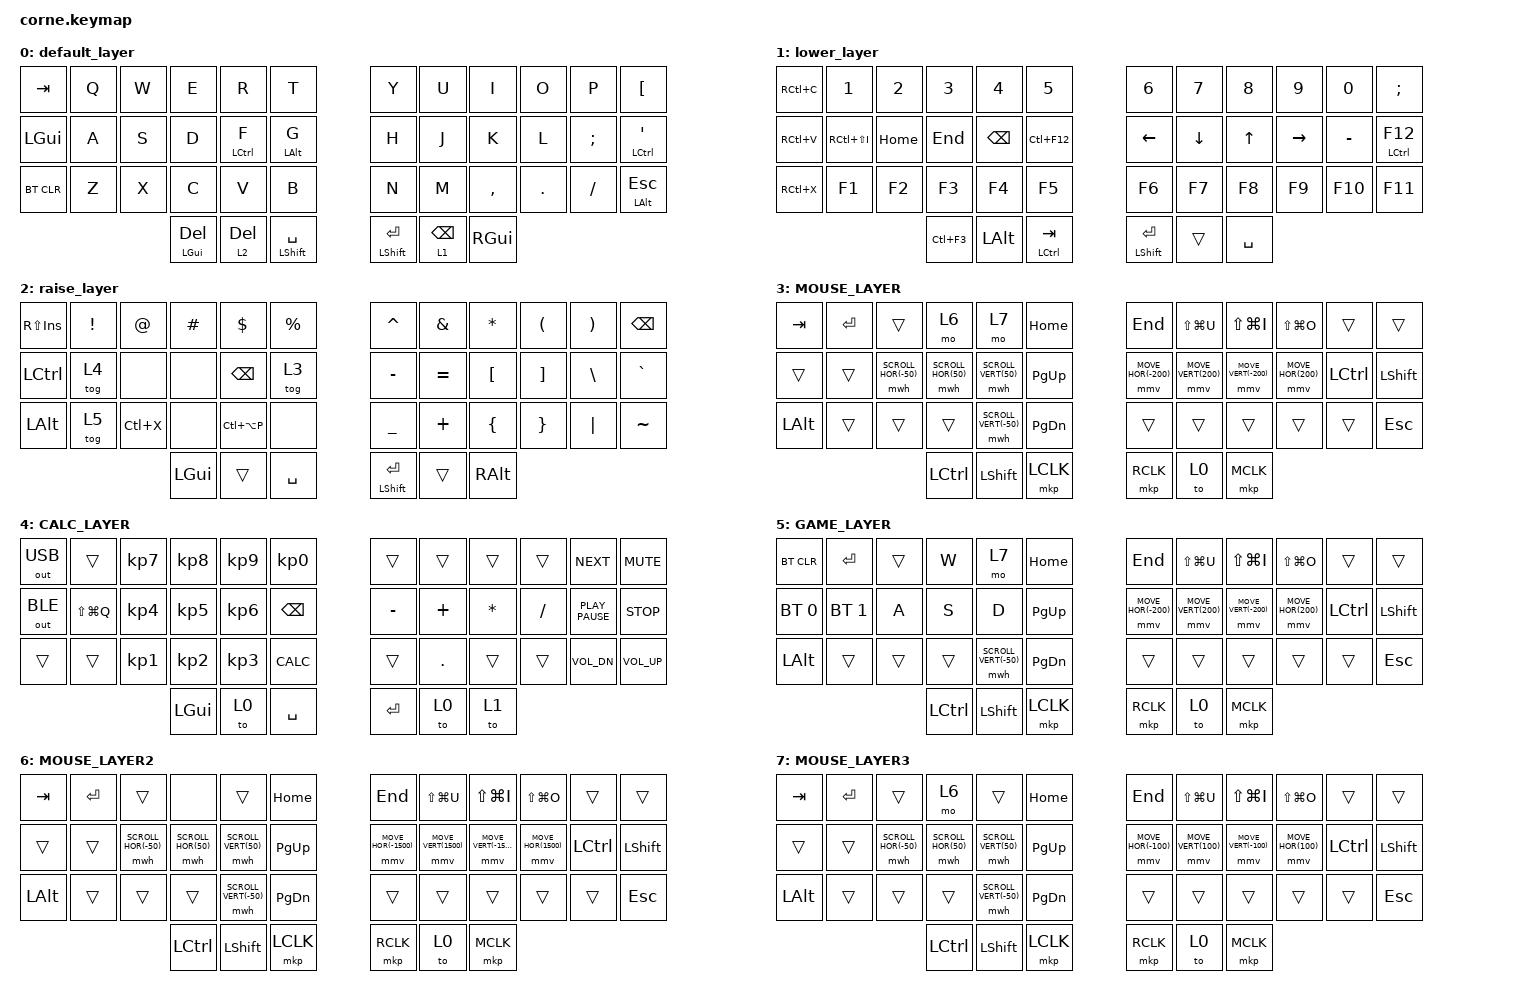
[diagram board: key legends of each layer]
/*
 * Copyright (c) 2020 The ZMK Contributors
 *
 * SPDX-License-Identifier: MIT
 */

#include <behaviors.dtsi>
#include <dt-bindings/zmk/mouse.h>
#include <dt-bindings/zmk/keys.h>
#include <dt-bindings/zmk/outputs.h>
#include <dt-bindings/zmk/bt.h>

&mmv {
    time-to-max-speed-ms = <500>;
    acceleration-exponent = <0>;
};

&mwh {
    time-to-max-speed-ms = <3000>;
    acceleration-exponent = <0>;
};


/ {
    behaviors {
        gqt: global-quick-tap {
            compatible = "zmk,behavior-hold-tap";
            label = "GLOBAL_QUICK_TAP";
            #binding-cells = <2>;
            flavor = "tap-preferred";
            tapping-term-ms = <200>;
            quick-tap-ms = <125>;
            global-quick-tap;
            bindings = <&kp>, <&kp>;
        };

        td0: tap_dance_0 {
            compatible = "zmk,behavior-tap-dance";
            label = "TAP_DANCE_CLOSE";
            #binding-cells = <0>;
            tapping-term-ms = <300>;
            bindings =
                <&kp SEMICOLON>,
                <&kp LS(LG(Q))>;
        };
        td1: tap_dance_1 {
            compatible = "zmk,behavior-tap-dance";
            label = "TAP_DANCE_WEB";
            #binding-cells = <0>;
            tapping-term-ms = <300>;
            bindings =
                <&kp COMMA>,
                <&kp RG(S)>;
        };
    };

    combos {
        compatible = "zmk,combos";

        vpn_toggle {
            bindings = <&kp LS(LG(P))>;
            key-positions = <10 1>;
        };

        web {
            bindings = <&kp RG(S)>;
            key-positions = <12 23>;
        };

        Lang_switch {
            bindings = <&kp RG(SPACE)>;
            key-positions = <16 19>;
        };

        close {
            bindings = <&kp LS(LG(Q))>;
            key-positions = <25 34>;
        };

        Editor {
            bindings = <&kp RG(Z)>;
            key-positions = <28 31>;
        };

        Save {
            bindings = <&kp LC(S)>;
            key-positions = <16 22>;
        };

        Messenger {
            bindings = <&kp RG(A)>;
            key-positions = <4 7>;
        };

        Cmd {
            bindings = <&kp RG(X)>;
            key-positions = <3 8>;
        };

        Ctrl_p {
            bindings = <&kp RC(P)>;
            key-positions = <13 22>;
        };

        arrow {
            bindings = <&arrow>;
            key-positions = <9 2>;
        };

        Change_win {
            bindings = <&kp LA(TAB)>;
            key-positions = <27 32>;
        };

        fat_arrow {
            bindings = <&fat_arrow>;
            key-positions = <26 33>;
        };

        vpn2_toggle {
            bindings = <&kp LS(LG(Y))>;
            key-positions = <25 34>;
        };
    };

    macros {
        arrow: arrow {
            compatible = "zmk,behavior-macro";
            label = "arrow";
            #binding-cells = <0>;
            bindings =
                <&macro_tap>,
                <&kp MINUS &kp GREATER_THAN>;
        };
        fat_arrow: fat_arrow {
            compatible = "zmk,behavior-macro";
            label = "fat_arrow";
            #binding-cells = <0>;
            bindings =
                <&macro_tap>,
                <&kp EQUAL &kp GREATER_THAN>;
        };
    };

    keymap {
        compatible = "zmk,keymap";

        default_layer {
            // -----------------------------------------------------------------------------------------
            // |  TAB |  Q  |  W  |  E  |  R  |  T  |   |  Y  |  U   |  I  |  O  |  P  | BKSP |
            // | CTRL |  A  |  S  |  D  |  F  |  G  |   |  H  |  J   |  K  |  L  |  ;  |  '   |
            // | SHFT |  Z  |  X  |  C  |  V  |  B  |   |  N  |  M   |  ,  |  .  |  /  | ESC  |
            //                    | GUI | LWR | SPC |   | ENT | RSE  | ALT |

            
            bindings = <
&kp TAB        &kp Q     &kp W     &kp E  &kp R  &kp T                                 &kp Y  &kp U  &kp I  &kp O  &kp P  &kp LBKT    
&kp LGUI       &kp A     &kp S     &kp D  &gqt LEFT_CONTROL F  &gqt LEFT_ALT G         &kp H  &kp J  &kp K  &kp L  &kp SEMICOLON  &mt LEFT_CONTROL SINGLE_QUOTE  
&bt BT_CLR       &kp Z     &kp X     &kp C  &kp V                                        &kp B  &kp N  &kp M  &kp COMMA  &kp DOT  &kp SLASH  &mt LEFT_ALT ESC  
                &mt LEFT_GUI DELETE  &lt 2 DEL  &mt LEFT_SHIFT SPACE                   &mt LEFT_SHIFT ENTER  &lt 1 BACKSPACE  &kp RGUI
            >;
        };

        lower_layer {
            // -----------------------------------------------------------------------------------------
            // |  TAB |  1  |  2  |  3  |  4  |  5  |   |  6  |  7  |  8  |  9  |  0  | BKSP |
            // | BTCLR| BT1 | BT2 | BT3 | BT4 | BT5 |   | LFT | DWN |  UP | RGT |     |      |
            // | SHFT |     |     |     |     |     |   |     |     |     |     |     |      |
            //                    | GUI |     | SPC |   | ENT |     | ALT |

            bindings = <
&kp RC(C)  &kp N1  &kp N2  &kp N3  &kp N4  &kp N5  &kp N6  &kp N7  &kp N8  &kp N9  &kp N0  &kp SEMICOLON  &kp RC(V)  &kp RC(LS(I))  &kp HOME  &kp END  &kp BACKSPACE  &kp LC(F12)  &kp LEFT  &kp DOWN  &kp UP  &kp RIGHT  &kp MINUS  &mt LEFT_CONTROL F12  &kp RC(X)  &kp F1  &kp F2  &kp F3  &kp F4  &kp F5  &kp F6  &kp F7  &kp F8  &kp F9  &kp F10  &kp F11  &kp LC(F3)  &kp LALT  &mt LEFT_CONTROL TAB  &mt LSHFT ENTER  &trans  &kp SPACE
            >;
        };

        raise_layer {
            // -----------------------------------------------------------------------------------------
            // |  TAB |  !  |  @  |  #  |  $  |  %  |   |  ^  |  &  |  *  |  (  |  )  | BKSP |
            // | CTRL |     |     |     |     |     |   |  -  |  =  |  [  |  ]  |  \  |  `   |
            // | SHFT |     |     |     |     |     |   |  _  |  +  |  {  |  }  | "|" |  ~   |
            //                    | GUI |     | SPC |   | ENT |     | ALT |

            bindings = <
&kp RS(INSERT)  &kp EXCLAMATION  &kp AT  &kp HASH  &kp DLLR  &kp PRCNT  &kp CARET  &kp AMPS  &kp STAR  &kp LPAR  &kp RPAR  &kp BSPC  &kp LCTRL  &tog 4  &none  &none  &kp BACKSPACE  &tog 3  &kp MINUS  &kp EQUAL  &kp LBKT  &kp RBKT  &kp BSLH  &kp GRAVE  &kp LALT  &tog 5  &kp LC(X)  &none  &kp LC(LA(P))  &none  &kp UNDER  &kp PLUS  &kp LBRC  &kp RBRC  &kp PIPE  &kp TILDE  &kp LGUI  &trans  &kp SPACE  &mt LSHFT ENTER  &trans  &kp RALT
            >;
        };

        MOUSE_LAYER {
            bindings = <
&kp TAB  &kp ENTER  &trans  &mo 6  &mo 7  &kp HOME  &kp END  &kp LS(LG(U))  &kp LS(LG(I))  &kp LS(LG(O))  &trans  &trans  &trans  &trans  &mwh SCROLL_HOR(-50)  &mwh SCROLL_HOR(50)  &mwh SCROLL_VERT(50)  &kp PAGE_UP  &mmv MOVE_HOR(-200)  &mmv MOVE_VERT(200)  &mmv MOVE_VERT(-200)  &mmv MOVE_HOR(200)  &kp LCTRL  &kp LSHFT  &kp LALT  &trans  &trans  &trans  &mwh SCROLL_VERT(-50)  &kp PAGE_DOWN  &trans  &trans  &trans  &trans  &trans  &kp ESC  &kp LCTRL  &kp LEFT_SHIFT  &mkp LCLK  &mkp RCLK  &to 0  &mkp MCLK
            >;
        };

        CALC_LAYER {
            bindings = <
&out OUT_USB  &trans  &kp KP_NUMBER_7  &kp KP_NUMBER_8  &kp KP_NUMBER_9  &kp KP_NUMBER_0  &trans  &trans  &trans  &trans  &kp K_NEXT  &kp K_MUTE  &out OUT_BLE  &kp LS(LG(Q))  &kp KP_NUMBER_4  &kp KP_NUMBER_5  &kp KP_NUMBER_6  &kp BACKSPACE  &kp MINUS  &kp PLUS  &kp STAR  &kp SLASH  &kp K_PLAY_PAUSE  &kp K_STOP  &trans  &trans  &kp KP_NUMBER_1  &kp KP_NUMBER_2  &kp KP_NUMBER_3  &kp K_CALC  &trans  &kp DOT  &trans  &trans  &kp K_VOL_DN  &kp K_VOL_UP  &kp LGUI  &to 0  &kp SPACE  &kp ENTER  &to 0  &to 1
            >;
        };

        GAME_LAYER {
            bindings = <
&bt BT_CLR  &kp ENTER  &trans  &kp W  &mo 7  &kp HOME  &kp END  &kp LS(LG(U))  &kp LS(LG(I))  &kp LS(LG(O))  &trans  &trans  &bt BT_SEL 0  &bt BT_SEL 1  &kp A  &kp S  &kp D  &kp PAGE_UP  &mmv MOVE_HOR(-200)  &mmv MOVE_VERT(200)  &mmv MOVE_VERT(-200)  &mmv MOVE_HOR(200)  &kp LCTRL  &kp LSHFT  &kp LALT  &trans  &trans  &trans  &mwh SCROLL_VERT(-50)  &kp PAGE_DOWN  &trans  &trans  &trans  &trans  &trans  &kp ESC  &kp LCTRL  &kp LEFT_SHIFT  &mkp LCLK  &mkp RCLK  &to 0  &mkp MCLK
            >;
        };

        MOUSE_LAYER2 {
            bindings = <
&kp TAB  &kp ENTER  &trans  &none  &trans  &kp HOME  &kp END  &kp LS(LG(U))  &kp LS(LG(I))  &kp LS(LG(O))  &trans  &trans  &trans  &trans  &mwh SCROLL_HOR(-50)  &mwh SCROLL_HOR(50)  &mwh SCROLL_VERT(50)  &kp PAGE_UP  &mmv MOVE_HOR(-1500)  &mmv MOVE_VERT(1500)  &mmv MOVE_VERT(-1500)  &mmv MOVE_HOR(1500)  &kp LCTRL  &kp LSHFT  &kp LALT  &trans  &trans  &trans  &mwh SCROLL_VERT(-50)  &kp PAGE_DOWN  &trans  &trans  &trans  &trans  &trans  &kp ESC  &kp LCTRL  &kp LEFT_SHIFT  &mkp LCLK  &mkp RCLK  &to 0  &mkp MCLK
            >;
        };

        MOUSE_LAYER3 {
            bindings = <
&kp TAB  &kp ENTER  &trans  &mo 6  &trans  &kp HOME  &kp END  &kp LS(LG(U))  &kp LS(LG(I))  &kp LS(LG(O))  &trans  &trans  &trans  &trans  &mwh SCROLL_HOR(-50)  &mwh SCROLL_HOR(50)  &mwh SCROLL_VERT(50)  &kp PAGE_UP  &mmv MOVE_HOR(-100)  &mmv MOVE_VERT(100)  &mmv MOVE_VERT(-100)  &mmv MOVE_HOR(100)  &kp LCTRL  &kp LSHFT  &kp LALT  &trans  &trans  &trans  &mwh SCROLL_VERT(-50)  &kp PAGE_DOWN  &trans  &trans  &trans  &trans  &trans  &kp ESC  &kp LCTRL  &kp LEFT_SHIFT  &mkp LCLK  &mkp RCLK  &to 0  &mkp MCLK
            >;
        };
    };
};
